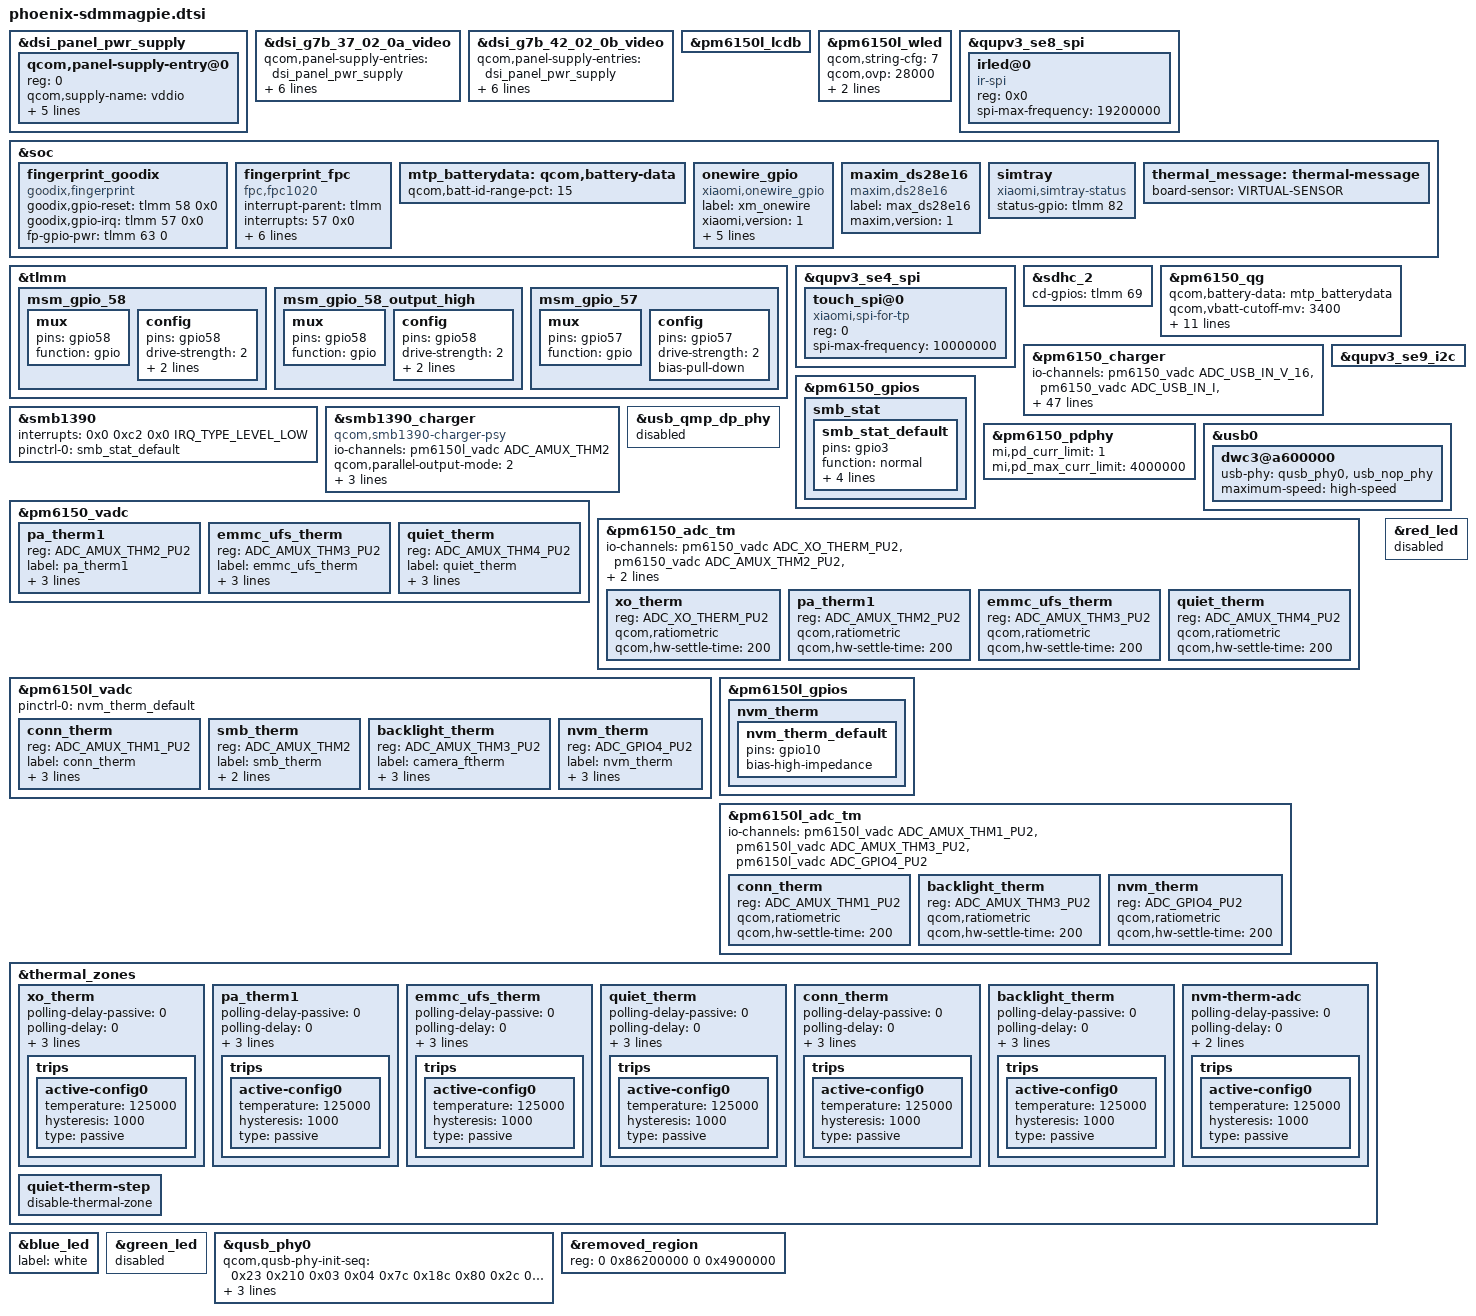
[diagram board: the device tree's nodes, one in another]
/* Copyright (c) 2018-2019, The Linux Foundation. All rights reserved.
 * Copyright (C) 2020 XiaoMi, Inc.
 *
 * This program is free software; you can redistribute it and/or modify
 * it under the terms of the GNU General Public License version 2 and
 * only version 2 as published by the Free Software Foundation.
 *
 * This program is distributed in the hope that it will be useful,
 * but WITHOUT ANY WARRANTY; without even the implied warranty of
 * MERCHANTABILITY or FITNESS FOR A PARTICULAR PURPOSE.  See the
 * GNU General Public License for more details.
 */
#include "phoenix-sdmmagpie-pinctrl.dtsi"
#include "xiaomi-sdmmagpie-common.dtsi"
#include "phoenix-sdmmagpie-camera-sensor.dtsi"

&dsi_panel_pwr_supply {
	qcom,panel-supply-entry@0 {
		reg = <0>;
		qcom,supply-name = "vddio";
		qcom,supply-min-voltage = <1900000>;
		qcom,supply-max-voltage = <1900000>;
		qcom,supply-enable-load = <32000>;
		qcom,supply-disable-load = <80>;
		qcom,supply-post-off-sleep = <20>;
	};
};

&dsi_g7b_37_02_0a_video {
	qcom,panel-supply-entries = <&dsi_panel_pwr_supply>;
	qcom,mdss-dsi-bl-pmic-control-type = "bl_ctrl_wled";
	qcom,mdss-dsi-bl-min-level = <2>;
	qcom,mdss-dsi-bl-max-level = <4095>;
	qcom,mdss-dsi-mode-sel-gpio-state = "single_port";
	qcom,platform-reset-gpio = <&pm6150l_gpios 9 0>;
};

&dsi_g7b_42_02_0b_video {
	qcom,panel-supply-entries = <&dsi_panel_pwr_supply>;
	qcom,mdss-dsi-bl-pmic-control-type = "bl_ctrl_wled";
	qcom,mdss-dsi-bl-min-level = <2>;
	qcom,mdss-dsi-bl-max-level = <4095>;
	qcom,mdss-dsi-mode-sel-gpio-state = "single_port";
	qcom,platform-reset-gpio = <&pm6150l_gpios 9 0>;
};

&pm6150l_lcdb {
	status = "okay";
};

&pm6150l_wled {
	status = "okay";
	qcom,string-cfg = <7>;
	qcom,ovp = <28000>;
	qcom,fs-current-limit = <22500>;
	qcom,cabc-sel = <1>;
};

&qupv3_se8_spi {
	status = "ok";
	irled@0 {
		compatible = "ir-spi";
		reg = <0x0>;
		status = "ok";
		spi-max-frequency = <19200000>;
	};
};

&soc {
	fingerprint_goodix {
		compatible = "goodix,fingerprint";
		goodix,gpio-reset = <&tlmm 58 0x0>;
		goodix,gpio-irq = <&tlmm 57 0x0>;
		fp-gpio-pwr = <&tlmm 63 0>;
		status = "ok";
	};
	fingerprint_fpc {
		status = "ok";
		compatible = "fpc,fpc1020";
		interrupt-parent = <&tlmm>;
		interrupts = <57 0x0>;
		fpc,gpio_rst    = <&tlmm 58 0x0>;
		fpc,gpio_irq    = <&tlmm 57 0x0>;
		fpc,gpio_vdd1v8 = <&tlmm 63 0>;
		pinctrl-names = "fpc1020_reset_reset",
		       "fpc1020_reset_active",
		       "fpc1020_irq_active";

		pinctrl-0 = <&msm_gpio_58>;
		pinctrl-1 = <&msm_gpio_58_output_high>;
		pinctrl-2 = <&msm_gpio_57>;

	};
	mtp_batterydata: qcom,battery-data {
		qcom,batt-id-range-pct = <15>;
		#include "batterydata-phoenix-G7BNVTBM4P-4500mah.dtsi"
		#include "batterydata-phoenix-G7BSWDBM4P-4500mah.dtsi"
	};

	onewire_gpio: onewire_gpio {
		compatible = "xiaomi,onewire_gpio";
		label = "xm_onewire";
		xiaomi,version = <1>;
		xiaomi,ow_gpio = <&tlmm 91 0x00>;
		xiaomi,gpio_number = <91>;
		mi,onewire-gpio-cfg-addr = <0x0395B000 0x4>;
		pinctrl-names = "onewire_active", "onewire_sleep";
		pinctrl-0 = <&onewire_gpio_active>;
		pinctrl-1 = <&onewire_gpio_sleep>;
		status = "ok";
	};
	maxim_ds28e16: maxim_ds28e16 {
		compatible = "maxim,ds28e16";
		label = "max_ds28e16";
		maxim,version = <1>;
		status = "ok";
	};

	simtray {
		compatible = "xiaomi,simtray-status";
		status-gpio = <&tlmm 82 0x00>;
	};

	thermal_message: thermal-message {
		board-sensor = "VIRTUAL-SENSOR";
	};
};

&tlmm {
	/* GPIO_58 : FP_RESET_N */
	msm_gpio_58: msm_gpio_58 {
		mux {
			 pins = "gpio58";
			 function = "gpio";
		};

		config {
			pins = "gpio58";
			drive-strength = <2>;
			bias-disable;
			output-low;
		};
	};

	/* GPIO_58 : FP_RESET_N, state device active*/
	msm_gpio_58_output_high: msm_gpio_58_output_high {
		mux {
			pins = "gpio58";
			function = "gpio";
		};

		config {
			pins = "gpio58";
			drive-strength = <2>;
			bias-disable;
			output-high;
		};
	};

	/* GPIO_57 : FP_INT_N */
	msm_gpio_57: msm_gpio_57 {
		mux {
			pins = "gpio57";
			function = "gpio";
		};

		config {
			pins = "gpio57";
			drive-strength = <2>;
			bias-pull-down;
		};
	};
};

#include "novatek-nt36xxx-spi.dtsi"

&qupv3_se4_spi {
	status = "ok";
	touch_spi@0 {
		compatible = "xiaomi,spi-for-tp";
		reg = <0>;
		status = "ok";
		spi-max-frequency = <10000000>;  //10M
	};
};

&sdhc_2 {

	cd-gpios = <&tlmm 69 GPIO_ACTIVE_HIGH>;

	status = "ok";
};


&pm6150_qg {
	qcom,battery-data = <&mtp_batterydata>;
	qcom,vbatt-cutoff-mv = <3400>;
	qcom,vbatt-low-mv = <3500>;
	qcom,vbatt-low-cold-mv = <3700>;
	qcom,vbatt-empty-mv = <3100>;
	qcom,vbatt-empty-cold-mv = <3100>;
	qcom,s3-entry-fifo-length = <2>;
	qcom,qg-iterm-ma = <300>;
	qcom,hold-soc-while-full;
	qcom,linearize-soc;
	qcom,cl-feedback-on;
	qcom,qg-ext-sns;
	qcom,tcss-enable;
};

&pm6150_charger {
	io-channels = <&pm6150_vadc ADC_USB_IN_V_16>,
		      <&pm6150_vadc ADC_USB_IN_I>,
		      <&pm6150_vadc ADC_CHG_TEMP>,
		      <&pm6150_vadc ADC_DIE_TEMP>,
		      <&pm6150l_vadc ADC_AMUX_THM1_PU2>,
		      <&pm6150_vadc ADC_SBUx>,
		      <&pm6150_vadc ADC_VPH_PWR>;
	io-channel-names = "usb_in_voltage",
			   "usb_in_current",
			   "chg_temp",
			   "die_temp",
			   "conn_temp",
			   "sbux_res",
			   "vph_voltage";
	qcom,battery-data = <&mtp_batterydata>;
	qcom,usb-icl-ua = <3000000>;
	qcom,fcc-max-ua = <5500000>;
	qcom,fv-max-uv = <4450000>;
	qcom,auto-recharge-soc = <99>;
	qcom,chg-term-src = <1>;
	qcom,chg-term-current-ma = <(-200)>;
	/delete-property/ qcom,fcc-stepping-enable;
	/delete-property/ qcom,step-charging-enable;
	qcom,sec-charger-config = <1>;
	/delete-property/ qcom,dynamic-fv-enable;
	qcom,thermal-mitigation = <3500000 3400000 3300000 3200000 3100000 3000000 2900000
				   2800000 2600000 2400000 2200000 2000000 1800000 1500000
				   1000000 500000>;
	qcom,thermal-mitigation-icl
				 = <2800000 2700000 2600000 2400000 2200000 2100000 2000000
				   2000000 2000000 1900000 1800000 1600000 1500000 1300000
				   800000 750000>;
	qcom,thermal-mitigation-dcp
				= <1800000 1800000 1800000 1800000 1800000 1800000 1800000
				   1800000 1800000 1700000 1600000 1400000 1200000 1100000
				   1100000 1000000>;
	qcom,thermal-mitigation-qc2
				= <1500000 1500000 1500000 1500000 1450000 1400000 1350000
				   1300000 1150000 1100000 1000000 900000 850000 750000
				   650000 500000>;
	qcom,thermal-fcc-qc3-normal
				= <3500000 3400000 3300000 3200000 3100000 3000000 2900000
				   2800000 2700000 2600000 2400000 2200000 2000000 2000000
				   750000 700000>;
	qcom,thermal-fcc-qc3-cp
				= <3500000 3500000 3500000 3500000 3400000 3300000 3200000
				   3100000 3000000 2800000 2600000 2400000 2200000 2000000
				   1000000 700000>;
	qcom,thermal-fcc-qc3-classb-cp
				= <5500000 4900000 4600000 4500000 4400000 4200000 3800000
				   3800000 3800000 3600000 3400000 3200000 3000000 2200000
				   800000 700000>;
	qcom,thermal-mitigation-pd-base
				 = <2800000 2700000 2600000 2400000 2200000 2100000 2000000
				   2000000 2000000 1900000 1800000 1600000 1500000 1300000
				   800000 750000>;
	qcom,thermal-fcc-pps-cp
				= <5500000 4900000 4600000 4500000 4400000 4200000 3800000
				   3800000 3800000 3600000 3400000 3200000 3000000 2200000
				   800000 700000>;
	dpdm-supply = <&qusb_phy0>;
	qcom,reg-dump-enable;
	qcom,temp-battery-id;
	qcom,temp-27W-enable;
	qcom,sw-jeita-enable;
	qcom,support-conn-therm;
	qcom,disable-suspend-on-collapse;

	vbus-disable-gpio = <&tlmm 68 GPIO_ACTIVE_HIGH>;
	pinctrl-names = "default", "vbus_disable_active", "vbus_disable_suspend";
	pinctrl-0 = <&vbus_disable_suspend>;
	pinctrl-1 = <&vbus_disable_active>;
	pinctrl-2 = <&vbus_disable_suspend>;

	qcom,distinguish-qc-class-ab;
	mi,six-pin-step-chg-params = <4390000  5500000
				4450000  3520000>;
	mi,six-pin-step-chg;
	mi,support-ffc;
};

&pm6150_gpios {
	smb_stat {
		smb_stat_default: smb_stat_default {
			pins = "gpio3";
			function = "normal";
			input-enable;
			bias-pull-up;
			qcom,pull-up-strength = <PMIC_GPIO_PULL_UP_30>;
			power-source = <0>;
		};
	};
};

&qupv3_se9_i2c {
	status = "ok";
	#include "smb1390.dtsi"
};

&smb1390 {
	/delete-property/ interrupts;
	interrupts = <0x0 0xc2 0x0 IRQ_TYPE_LEVEL_LOW>;
	pinctrl-names = "default";
	pinctrl-0 = <&smb_stat_default>;
	status = "ok";
};

&smb1390_charger {
	compatible = "qcom,smb1390-charger-psy";
	io-channels = <&pm6150l_vadc ADC_AMUX_THM2>;
	io-channel-names = "cp_die_temp";
	status = "ok";
	qcom,parallel-output-mode = <2>;
	qcom,max-cutoff-soc = <92>;
	qcom,min-ilim-ua = <1100000>;
	mi,six-pin-batt;
};

&pm6150_pdphy {
	mi,pd_curr_limit = <1>;
	mi,pd_max_curr_limit = <4000000>;
};

&usb0 {
	dwc3@a600000 {
		usb-phy = <&qusb_phy0>, <&usb_nop_phy>;
		maximum-speed = "high-speed";
	};
};

&usb_qmp_dp_phy {
	status = "disabled";
};


&pm6150_vadc {
	pa_therm1 {
		reg = <ADC_AMUX_THM2_PU2>;
		label = "pa_therm1";
		qcom,ratiometric;
		qcom,hw-settle-time = <200>;
		qcom,pre-scaling = <1 1>;
	};

	emmc_ufs_therm {
		reg = <ADC_AMUX_THM3_PU2>;
		label = "emmc_ufs_therm";
		qcom,ratiometric;
		qcom,hw-settle-time = <200>;
		qcom,pre-scaling = <1 1>;
	};

	quiet_therm {
		reg = <ADC_AMUX_THM4_PU2>;
		label = "quiet_therm";
		qcom,ratiometric;
		qcom,hw-settle-time = <200>;
		qcom,pre-scaling = <1 1>;
	};
};

&pm6150_adc_tm {
	io-channels = <&pm6150_vadc ADC_XO_THERM_PU2>,
			<&pm6150_vadc ADC_AMUX_THM2_PU2>,
			<&pm6150_vadc ADC_AMUX_THM3_PU2>,
			<&pm6150_vadc ADC_AMUX_THM4_PU2>;

	/* Channel nodes */
	xo_therm {
		reg = <ADC_XO_THERM_PU2>;
		qcom,ratiometric;
		qcom,hw-settle-time = <200>;
	};

	pa_therm1 {
		reg = <ADC_AMUX_THM2_PU2>;
		qcom,ratiometric;
		qcom,hw-settle-time = <200>;
	};

	emmc_ufs_therm {
		reg = <ADC_AMUX_THM3_PU2>;
		qcom,ratiometric;
		qcom,hw-settle-time = <200>;
	};

	quiet_therm {
		reg = <ADC_AMUX_THM4_PU2>;
		qcom,ratiometric;
		qcom,hw-settle-time = <200>;
	};
};

&pm6150l_vadc {
	pinctrl-names = "default";
	pinctrl-0 = <&nvm_therm_default>;

	conn_therm {
		reg = <ADC_AMUX_THM1_PU2>;
		label = "conn_therm";
		qcom,ratiometric;
		qcom,hw-settle-time = <200>;
		qcom,pre-scaling = <1 1>;
	};

	smb_therm {
		reg = <ADC_AMUX_THM2>;
		label = "smb_therm";
		qcom,hw-settle-time = <200>;
		qcom,pre-scaling = <1 1>;
	};

	backlight_therm {
		reg = <ADC_AMUX_THM3_PU2>;
		label = "camera_ftherm";
		qcom,ratiometric;
		qcom,hw-settle-time = <200>;
		qcom,pre-scaling = <1 1>;
	};

	nvm_therm {
		reg = <ADC_GPIO4_PU2>;
		label = "nvm_therm";
		qcom,ratiometric;
		qcom,hw-settle-time = <200>;
		qcom,pre-scaling = <1 1>;
	};
};

&pm6150l_gpios {
	nvm_therm {
		nvm_therm_default: nvm_therm_default {
			pins = "gpio10";
			bias-high-impedance;
		};
	};
};

&pm6150l_adc_tm {
	io-channels = <&pm6150l_vadc ADC_AMUX_THM1_PU2>,
			<&pm6150l_vadc ADC_AMUX_THM3_PU2>,
			<&pm6150l_vadc ADC_GPIO4_PU2>;

	/* Channel nodes */
	conn_therm {
		reg = <ADC_AMUX_THM1_PU2>;
		qcom,ratiometric;
		qcom,hw-settle-time = <200>;
	};

	backlight_therm {
		reg = <ADC_AMUX_THM3_PU2>;
		qcom,ratiometric;
		qcom,hw-settle-time = <200>;
	};

	nvm_therm {
		reg = <ADC_GPIO4_PU2>;
		qcom,ratiometric;
		qcom,hw-settle-time = <200>;
	};
};

&thermal_zones {

	xo_therm {
		polling-delay-passive = <0>;
		polling-delay = <0>;
		thermal-governor = "user_space";
		thermal-sensors = <&pm6150_adc_tm ADC_XO_THERM_PU2>;
		trips {
			active-config0 {
				temperature = <125000>;
				hysteresis = <1000>;
				type = "passive";
			};
		};
	};

	pa_therm1 {
		polling-delay-passive = <0>;
		polling-delay = <0>;
		thermal-governor = "user_space";
		thermal-sensors = <&pm6150_adc_tm ADC_AMUX_THM2_PU2>;
		trips {
			active-config0 {
				temperature = <125000>;
				hysteresis = <1000>;
				type = "passive";
			};
		};
	};

	emmc_ufs_therm {
		polling-delay-passive = <0>;
		polling-delay = <0>;
		thermal-governor = "user_space";
		thermal-sensors = <&pm6150_adc_tm ADC_AMUX_THM3_PU2>;
		trips {
			active-config0 {
				temperature = <125000>;
				hysteresis = <1000>;
				type = "passive";
			};
		};
	};

	quiet_therm {
		polling-delay-passive = <0>;
		polling-delay = <0>;
		thermal-governor = "user_space";
		thermal-sensors = <&pm6150_adc_tm ADC_AMUX_THM4_PU2>;
		trips {
			active-config0 {
				temperature = <125000>;
				hysteresis = <1000>;
				type = "passive";
			};
		};
	};

	conn_therm {
		polling-delay-passive = <0>;
		polling-delay = <0>;
		thermal-governor = "user_space";
		thermal-sensors = <&pm6150l_adc_tm ADC_AMUX_THM1_PU2>;
		trips {
			active-config0 {
				temperature = <125000>;
				hysteresis = <1000>;
				type = "passive";
			};
		};
	};

	backlight_therm {
		polling-delay-passive = <0>;
		polling-delay = <0>;
		thermal-governor = "user_space";
		thermal-sensors = <&pm6150l_adc_tm ADC_AMUX_THM3_PU2>;
		trips {
			active-config0 {
				temperature = <125000>;
				hysteresis = <1000>;
				type = "passive";
			};
		};
	};

	nvm-therm-adc {
		polling-delay-passive = <0>;
		polling-delay = <0>;
		thermal-governor = "user_space";
		thermal-sensors = <&pm6150l_adc_tm ADC_GPIO4_PU2>;
		trips {
			active-config0 {
				temperature = <125000>;
				hysteresis = <1000>;
				type = "passive";
			};
		};
	};

	quiet-therm-step {
		disable-thermal-zone;
	};
};

&blue_led {
	label = "white";
};

&green_led {
	status = "disabled";
};

&red_led {
	status = "disabled";
};

&qusb_phy0 {
	qcom,qusb-phy-init-seq =
		/* <value reg_offset> */
		   <0x23 0x210 /* PWR_CTRL1 */
		    0x03 0x04  /* PLL_ANALOG_CONTROLS_TWO */
		    0x7c 0x18c /* PLL_CLOCK_INVERTERS */
		    0x80 0x2c  /* PLL_CMODE */
		    0x0a 0x184 /* PLL_LOCK_DELAY */
		    0x19 0xb4  /* PLL_DIGITAL_TIMERS_TWO */
		    0x40 0x194 /* PLL_BIAS_CONTROL_1 */
		    0x14 0x198  /* PLL_BIAS_CONTROL_2 */
		    0x21 0x214 /* PWR_CTRL2 */
		    0x00 0x220 /* IMP_CTRL1 */
		    0x18 0x224 /* IMP_CTRL2 */
		    0x07 0x240  /* TUNE1 */
		    0x08 0x244  /* TUNE2 */
		    0xca 0x248 /* TUNE3 */
		    0x02 0x24c /* TUNE4 */
		    0x03 0x250 /* TUNE5 */
		    0x00 0x23c /* CHG_CTRL2 */
		    0x22 0x210>; /* PWR_CTRL1 */
		    mi,no-efuse-tune;

	qcom,qusb-phy-host-init-seq =
		/* <value reg_offset> */
		   <0x23 0x210 /* PWR_CTRL1 */
		    0x03 0x04  /* PLL_ANALOG_CONTROLS_TWO */
		    0x7c 0x18c /* PLL_CLOCK_INVERTERS */
		    0x80 0x2c  /* PLL_CMODE */
		    0x0a 0x184 /* PLL_LOCK_DELAY */
		    0x19 0xb4  /* PLL_DIGITAL_TIMERS_TWO */
		    0x40 0x194 /* PLL_BIAS_CONTROL_1 */
		    0x20 0x198 /* PLL_BIAS_CONTROL_2 */
		    0x21 0x214 /* PWR_CTRL2 */
		    0x00 0x220 /* IMP_CTRL1 */
		    0x18 0x224 /* IMP_CTRL2 */
		    0x37 0x240 /* TUNE1 */
		    0x2A 0x244 /* TUNE2 */
		    0xca 0x248 /* TUNE3 */
		    0x04 0x24c /* TUNE4 */
		    0x03 0x250 /* TUNE5 */
		    0x00 0x23c /* CHG_CTRL2 */
		    0x22 0x210>; /* PWR_CTRL1 */
};

/* Enlarge TZ memory size to 62M */
&removed_region {
       reg = <0 0x86200000 0 0x4900000>;
};
